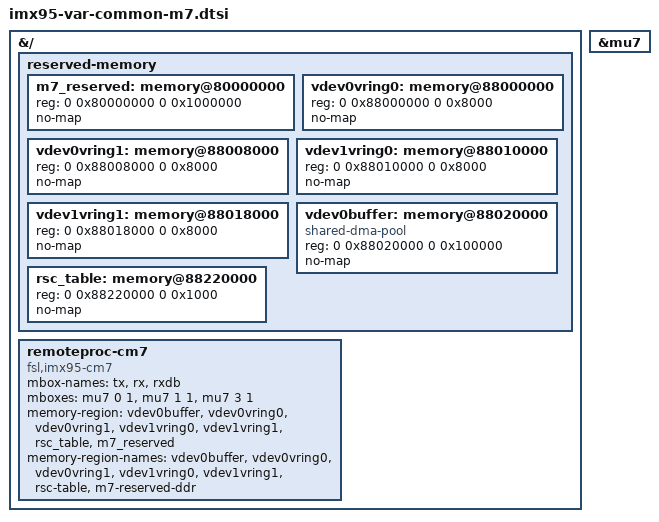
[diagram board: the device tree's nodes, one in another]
// SPDX-License-Identifier: (GPL-2.0+ OR MIT)
/*
 * Common Cortex-M7 configuration for Variscite i.MX95 modules
 *
 * Copyright (C) 2026 Variscite Ltd. - https://www.variscite.com/
 *
 */

&{/} {
	#address-cells = <2>;
	#size-cells = <2>;

	reserved-memory {
		#address-cells = <2>;
		#size-cells = <2>;
		ranges;

		m7_reserved: memory@80000000 {
			reg = <0 0x80000000 0 0x1000000>;
			no-map;
		};

		vdev0vring0: memory@88000000 {
			reg = <0 0x88000000 0 0x8000>;
			no-map;
		};

		vdev0vring1: memory@88008000 {
			reg = <0 0x88008000 0 0x8000>;
			no-map;
		};

		vdev1vring0: memory@88010000 {
			reg = <0 0x88010000 0 0x8000>;
			no-map;
		};

		vdev1vring1: memory@88018000 {
			reg = <0 0x88018000 0 0x8000>;
			no-map;
		};

		vdev0buffer: memory@88020000 {
			compatible = "shared-dma-pool";
			reg = <0 0x88020000 0 0x100000>;
			no-map;
		};

		rsc_table: memory@88220000 {
			reg = <0 0x88220000 0 0x1000>;
			no-map;
		};
	};

	remoteproc-cm7 {
		compatible = "fsl,imx95-cm7";
		mbox-names = "tx", "rx", "rxdb";
		mboxes = <&mu7 0 1
			  &mu7 1 1
			  &mu7 3 1>;
		memory-region = <&vdev0buffer>, <&vdev0vring0>, <&vdev0vring1>,
				<&vdev1vring0>, <&vdev1vring1>, <&rsc_table>,
				<&m7_reserved>;
		memory-region-names = "vdev0buffer", "vdev0vring0", "vdev0vring1",
				      "vdev1vring0", "vdev1vring1", "rsc-table",
				      "m7-reserved-ddr";
	};
};

&mu7 {
	status = "okay";
};
